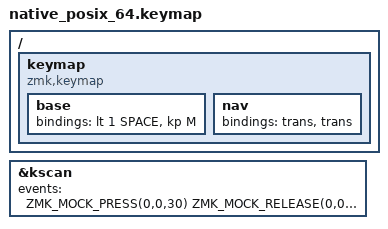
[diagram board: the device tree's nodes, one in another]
#include <dt-bindings/zmk/keys.h>
#include <behaviors.dtsi>
#include <dt-bindings/zmk/kscan_mock.h>
#include "../../../config/hold_tap.dtsi"

/ {
    keymap {
        compatible = "zmk,keymap";
        base { bindings = <&lt 1 SPACE &kp M>; };
        nav { bindings = <&trans &trans>; };
    };
};
&kscan {
    events = <
        ZMK_MOCK_PRESS(0,0,30) ZMK_MOCK_RELEASE(0,0,30)
        ZMK_MOCK_PRESS(0,0,30) ZMK_MOCK_RELEASE(0,0,30)
        ZMK_MOCK_PRESS(0,0,30) ZMK_MOCK_RELEASE(0,0,30)
        ZMK_MOCK_PRESS(0,0,30) ZMK_MOCK_RELEASE(0,0,30)
        ZMK_MOCK_PRESS(0,0,30) ZMK_MOCK_RELEASE(0,0,30)
        ZMK_MOCK_PRESS(0,0,30) ZMK_MOCK_RELEASE(0,0,30)
        ZMK_MOCK_PRESS(0,0,30) ZMK_MOCK_RELEASE(0,0,30)
        ZMK_MOCK_PRESS(0,0,30) ZMK_MOCK_RELEASE(0,0,30)
        ZMK_MOCK_PRESS(0,0,30) ZMK_MOCK_RELEASE(0,0,30)
        ZMK_MOCK_PRESS(0,0,30) ZMK_MOCK_RELEASE(0,0,30)
    >;
};
